# L4PER_PRM register map
Vendor: Texas Instruments
Registers are 32-bit, access per field, reset 0x0 unless marked. A register's access mark holds for its fields unless they carry their own. Offsets are as the file gives them; [hi:lo] are bit positions; {n}, {i} and the like mark numbered series; 'fields as' and 'values as' point back to an identical list.

## L4PER_PRM (part 2 of 2)
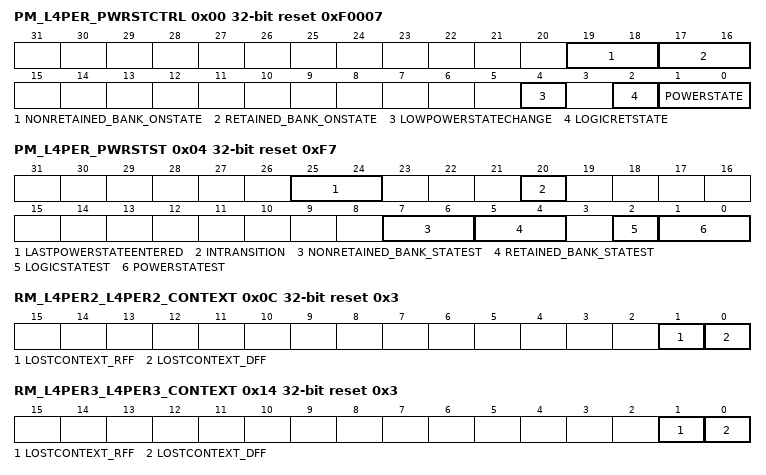
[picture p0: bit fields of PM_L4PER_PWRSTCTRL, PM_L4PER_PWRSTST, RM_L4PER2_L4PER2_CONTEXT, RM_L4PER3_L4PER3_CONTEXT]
0x00 PM_L4PER_PWRSTCTRL reset 0xF0007 — This register controls the L4PER power state to reach upon a domain sleep transition
  [19:18] NONRETAINED_BANK_ONSTATE ro — NONRETAINED_BANK state when domain is ON.
    3=MEM_ON (Memory bank is on when the domain is ON.)
  [17:16] RETAINED_BANK_ONSTATE ro — RETAINED_BANK state when domain is ON.
    3=MEM_ON (Memory bank is on when the domain is ON.)
  [4] LOWPOWERSTATECHANGE rw — Power state change request when domain has already performed a sleep transition. Allows going into deeper low power state without waking up the power domain.
    0=DIS (Do not request a low power state change.); 1=EN (Request a low power state change. This bit is automatically cleared when the power state is effectively changed or when power state is ON.)
  [2] LOGICRETSTATE rw — Logic state when power domain is RETENTION
    0=LOGIC_OFF (Only retention registers are retained and remaing logic is off when the domain is in RETENTION state.); 1=LOGIC_RET (Whole logic is retained when domain is in RETENTION state.)
  [1:0] POWERSTATE rw — Power state control
    1=RET (Reserved); 2=INACT (Reserved); 3=ON (ON State)
0x04 PM_L4PER_PWRSTST reset 0xF7 — This register provides a status on the current L4PER power domain state. [warm reset insensitive]
  [25:24] LASTPOWERSTATEENTERED rw — Last low power state entered. Set to 0x3 upon write of the same only. This register is intended for debug purpose only.
    0=OFF (Power domain was previously OFF); 1=RET (Reserved); 2=INACTIVE (Reserved); 3=ON (Power domain was previously ON-ACTIVE)
  [20] INTRANSITION ro — Domain transition status
    0=NO (No on-going transition on power domain); 1=ONGOING (Power domain transition is in progress.)
  [7:6] NONRETAINED_BANK_STATEST ro — NONRETAINED_BANK state status
    0=MEM_OFF (Memory is OFF); 3=MEM_ON (Memory is ON)
  [5:4] RETAINED_BANK_STATEST ro — RETAINED_BANK state status
    0=MEM_OFF (Memory is OFF); 1=MEM_RET (Reserved); 3=MEM_ON (Memory is ON)
  [2] LOGICSTATEST ro — Logic state status
    0=OFF (Reserved); 1=ON (Logic in domain is ON)
  [1:0] POWERSTATEST ro — Current power state status
    1=RET (Reserved); 2=INACTIVE (Reserved); 3=ON (Power domain is ON-ACTIVE)
0x0C RM_L4PER2_L4PER2_CONTEXT reset 0x3 — This register contains dedicated L4_PER2 context statuses. [warm reset insensitive]
  [1] LOSTCONTEXT_RFF rw — Specify if RFF-based context has been lost due to a previous power transition or other reset source. (set upon assertion of L4PER_PWRON_RET_RST signal)
    0=MAINTAINED (Context has been maintained); 1=LOST (Context has been lost)
  [0] LOSTCONTEXT_DFF rw — Specify if DFF-based context has been lost due to a previous power transition or other reset source. (set upon assertion of L4PER_RST signal)
    values as LOSTCONTEXT_RFF
0x14 RM_L4PER3_L4PER3_CONTEXT reset 0x3 — This register contains dedicated L4_PER3 context statuses. [warm reset insensitive]
  fields as RM_L4PER2_L4PER2_CONTEXT
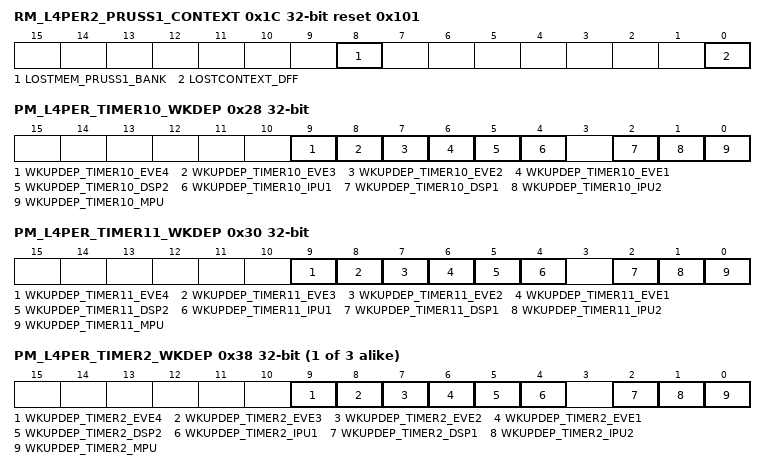
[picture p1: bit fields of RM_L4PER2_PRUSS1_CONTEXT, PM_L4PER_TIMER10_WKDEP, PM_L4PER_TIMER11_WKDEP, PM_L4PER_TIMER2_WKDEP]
0x1C RM_L4PER2_PRUSS1_CONTEXT reset 0x101 — This register contains dedicated PRU-ICSS1 context statuses. [warm reset insensitive]Programmable Real-Time Unit and Industrial Communication Subsystems (PRU-ICSS) is not supported in this family of devices.
  [8] LOSTMEM_PRUSS1_BANK rw — Specify if memory-based context in PRU-ICSS memory bank has been lost due to a previous power transition or other reset source.
    values as RM_L4PER2_L4PER2_CONTEXT.LOSTCONTEXT_RFF
  [0] LOSTCONTEXT_DFF rw — Specify if DFF-based context has been lost due to a previous power transition or other reset source. (set upon assertion of L3INIT_RST signal)
    values as RM_L4PER2_L4PER2_CONTEXT.LOSTCONTEXT_RFF
0x28 PM_L4PER_TIMER10_WKDEP — This register controls wakeup dependency based on TIMER10 service requests.
  [9] WKUPDEP_TIMER10_EVE4 rw — Wakeup dependency from TIMER10 module (SWakeup IRQ signal) towards EVE4 + L3_MAIN1 + L4PER1 + L4PER2 + L4PER3 domainsEVE4 is not supported in this family of devices.
    0=DISABLED (Dependency is disabled); 1=ENABLED (Dependency is enabled)
  [8] WKUPDEP_TIMER10_EVE3 rw — Wakeup dependency from TIMER10 module (SWakeup IRQ signal) towards EVE3 + L3_MAIN1 + L4PER1 + L4PER2 + L4PER3 domainsEVE3 is not supported in this family of devices.
    values as WKUPDEP_TIMER10_EVE4
  [7] WKUPDEP_TIMER10_EVE2 rw — Wakeup dependency from TIMER10 module (SWakeup IRQ signal) towards EVE2 + L3_MAIN1 + L4PER1 + L4PER2 + L4PER3 domains
    values as WKUPDEP_TIMER10_EVE4
  [6] WKUPDEP_TIMER10_EVE1 rw — Wakeup dependency from TIMER10 module (SWakeup IRQ signal) towards EVE1 + L3_MAIN1 + L4PER1 + L4PER2 + L4PER3 domains
    values as WKUPDEP_TIMER10_EVE4
  [5] WKUPDEP_TIMER10_DSP2 rw — Wakeup dependency from TIMER10 module (SWakeup IRQ signal) towards DSP2 + L3_MAIN1 + L4PER1 + L4PER2 + L4PER3 domains
    values as WKUPDEP_TIMER10_EVE4
  [4] WKUPDEP_TIMER10_IPU1 rw — Wakeup dependency from TIMER10 module (SWakeup IRQ signal) towards IPU1 + L3_MAIN1 + L4PER1 + L4PER2 + L4PER3 domains
    values as WKUPDEP_TIMER10_EVE4
  [2] WKUPDEP_TIMER10_DSP1 rw — Wakeup dependency from TIMER10 module (SWakeup IRQ signal) towards DSP1 + L3_MAIN1 + L4PER1 + L4PER2 + L4PER3 domains
    values as WKUPDEP_TIMER10_EVE4
  [1] WKUPDEP_TIMER10_IPU2 rw — Wakeup dependency from TIMER10 module (SWakeup IRQ signal) towards IPU2 + L3_MAIN1 + L4PER1 + L4PER2 + L4PER3 domains
    0=Dependency_is_disabled; 1=Dependency_is_enabled
  [0] WKUPDEP_TIMER10_MPU rw — Wakeup dependency from TIMER10 module (SWakeup IRQ signal) towards MPU + L3_MAIN1 + L4PER1 + L4PER2 + L4PER3 domains
    values as WKUPDEP_TIMER10_EVE4
0x2C RM_L4PER_TIMER10_CONTEXT reset 0x1 — This register contains dedicated TIMER10 context statuses. [warm reset insensitive]
  [0] LOSTCONTEXT_DFF rw — Specify if DFF-based context has been lost due to a previous power transition or other reset source. (set upon assertion of L4PER_RST signal)
    values as RM_L4PER2_L4PER2_CONTEXT.LOSTCONTEXT_RFF
0x30 PM_L4PER_TIMER11_WKDEP — This register controls wakeup dependency based on TIMER11 service requests.
  [9] WKUPDEP_TIMER11_EVE4 rw — Wakeup dependency from TIMER11 module (SWakeup IRQ signal) towards EVE4 + L3_MAIN1 + L4PER1 + L4PER2 + L4PER3 domainsEVE4 is not supported in this family of devices.
    values as PM_L4PER_TIMER10_WKDEP.WKUPDEP_TIMER10_EVE4
  [8] WKUPDEP_TIMER11_EVE3 rw — Wakeup dependency from TIMER11 module (SWakeup IRQ signal) towards EVE3 + L3_MAIN1 + L4PER1 + L4PER2 + L4PER3 domainsEVE3 is not supported in this family of devices.
    values as PM_L4PER_TIMER10_WKDEP.WKUPDEP_TIMER10_EVE4
  [7] WKUPDEP_TIMER11_EVE2 rw — Wakeup dependency from TIMER11 module (SWakeup IRQ signal) towards EVE2 + L3_MAIN1 + L4PER1 + L4PER2 + L4PER3 domains
    values as PM_L4PER_TIMER10_WKDEP.WKUPDEP_TIMER10_EVE4
  [6] WKUPDEP_TIMER11_EVE1 rw — Wakeup dependency from TIMER11 module (SWakeup IRQ signal) towards EVE1 + L3_MAIN1 + L4PER1 + L4PER2 + L4PER3 domains
    values as PM_L4PER_TIMER10_WKDEP.WKUPDEP_TIMER10_EVE4
  [5] WKUPDEP_TIMER11_DSP2 rw — Wakeup dependency from TIMER11 module (SWakeup IRQ signal) towards DSP2 + L3_MAIN1 + L4PER1 + L4PER2 + L4PER3 domains
    values as PM_L4PER_TIMER10_WKDEP.WKUPDEP_TIMER10_EVE4
  [4] WKUPDEP_TIMER11_IPU1 rw — Wakeup dependency from TIMER11 module (SWakeup IRQ signal) towards IPU1 + L3_MAIN1 + L4PER1 + L4PER2 + L4PER3 domains
    values as PM_L4PER_TIMER10_WKDEP.WKUPDEP_TIMER10_EVE4
  [2] WKUPDEP_TIMER11_DSP1 rw — Wakeup dependency from TIMER11 module (SWakeup IRQ signal) towards DSP1 + L3_MAIN1 + L4PER1 + L4PER2 + L4PER3 domains
    values as PM_L4PER_TIMER10_WKDEP.WKUPDEP_TIMER10_EVE4
  [1] WKUPDEP_TIMER11_IPU2 rw — Wakeup dependency from TIMER11 module (SWakeup IRQ signal) towards IPU2 + L3_MAIN1 + L4PER1 + L4PER2 + L4PER3 domains
    0=Dependency_is_disabled; 1=Dependency_is_enabled
  [0] WKUPDEP_TIMER11_MPU rw — Wakeup dependency from TIMER11 module (SWakeup IRQ signal) towards MPU + L3_MAIN1 + L4PER1 + L4PER2 + L4PER3 domains
    values as PM_L4PER_TIMER10_WKDEP.WKUPDEP_TIMER10_EVE4
0x34 RM_L4PER_TIMER11_CONTEXT reset 0x1 — This register contains dedicated TIMER11 context statuses. [warm reset insensitive]
  fields as RM_L4PER_TIMER10_CONTEXT
{0x28+8i} PM_L4PER_TIMER{i}_WKDEP (i=2..4) — This register controls wakeup dependency based on TIMER{i} service requests.
  [9] WKUPDEP_TIMER{i}_EVE4 rw — Wakeup dependency from TIMER{i} module (SWakeup IRQ signal) towards EVE4 + L3_MAIN1 + L4PER1 + L4PER2 + L4PER3 domainsEVE4 is not supported in this family of devices.
    values as PM_L4PER_TIMER10_WKDEP.WKUPDEP_TIMER10_EVE4
  [8] WKUPDEP_TIMER{i}_EVE3 rw — Wakeup dependency from TIMER{i} module (SWakeup IRQ signal) towards EVE3 + L3_MAIN1 + L4PER1 + L4PER2 + L4PER3 domainsEVE3 is not supported in this family of devices.
    values as PM_L4PER_TIMER10_WKDEP.WKUPDEP_TIMER10_EVE4
  [7] WKUPDEP_TIMER{i}_EVE2 rw — Wakeup dependency from TIMER{i} module (SWakeup IRQ signal) towards EVE2 + L3_MAIN1 + L4PER1 + L4PER2 + L4PER3 domains
    values as PM_L4PER_TIMER10_WKDEP.WKUPDEP_TIMER10_EVE4
  [6] WKUPDEP_TIMER{i}_EVE1 rw — Wakeup dependency from TIMER{i} module (SWakeup IRQ signal) towards EVE1 + L3_MAIN1 + L4PER1 + L4PER2 + L4PER3 domains
    values as PM_L4PER_TIMER10_WKDEP.WKUPDEP_TIMER10_EVE4
  [5] WKUPDEP_TIMER{i}_DSP2 rw — Wakeup dependency from TIMER{i} module (SWakeup IRQ signal) towards DSP2 + L3_MAIN1 + L4PER1 + L4PER2 + L4PER3 domains
    values as PM_L4PER_TIMER10_WKDEP.WKUPDEP_TIMER10_EVE4
  [4] WKUPDEP_TIMER{i}_IPU1 rw — Wakeup dependency from TIMER{i} module (SWakeup IRQ signal) towards IPU1 + L3_MAIN1 + L4PER1 + L4PER2 + L4PER3 domains
    values as PM_L4PER_TIMER10_WKDEP.WKUPDEP_TIMER10_EVE4
  [2] WKUPDEP_TIMER{i}_DSP1 rw — Wakeup dependency from TIMER{i} module (SWakeup IRQ signal) towards DSP1 + L3_MAIN1 + L4PER1 + L4PER2 + L4PER3 domains
    values as PM_L4PER_TIMER10_WKDEP.WKUPDEP_TIMER10_EVE4
  [1] WKUPDEP_TIMER{i}_IPU2 rw — Wakeup dependency from TIMER{i} module (SWakeup IRQ signal) towards IPU2 + L3_MAIN1 + L4PER1 + L4PER2 + L4PER3 domains
    0=Dependency_is_disabled; 1=Dependency_is_enabled
  [0] WKUPDEP_TIMER{i}_MPU rw — Wakeup dependency from TIMER{i} module (SWakeup IRQ signal) towards MPU + L3_MAIN1 + L4PER1 + L4PER2 + L4PER3 domains
    values as PM_L4PER_TIMER10_WKDEP.WKUPDEP_TIMER10_EVE4
{0x2C+8i} RM_L4PER_TIMER{i}_CONTEXT reset 0x1 (i=2..4) — This register contains dedicated TIMER{i} context statuses. [warm reset insensitive]
  fields as RM_L4PER_TIMER10_CONTEXT
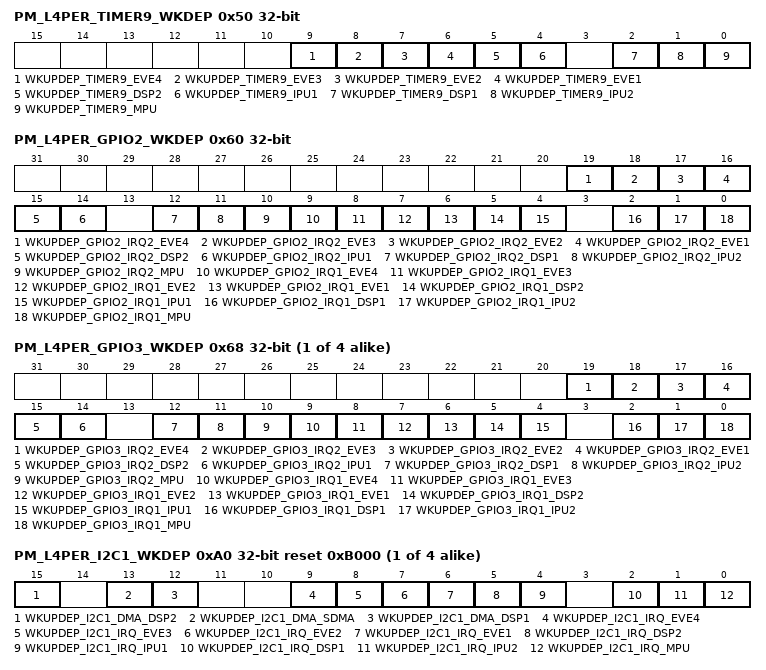
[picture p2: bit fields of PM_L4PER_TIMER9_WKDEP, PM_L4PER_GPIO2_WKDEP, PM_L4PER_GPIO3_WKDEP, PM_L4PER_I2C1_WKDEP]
0x50 PM_L4PER_TIMER9_WKDEP — This register controls wakeup dependency based on TIMER9 service requests.
  [9] WKUPDEP_TIMER9_EVE4 rw — Wakeup dependency from TIMER9 module (SWakeup IRQ signal) towards EVE4 + L3_MAIN1 + L4PER1 + L4PER2 + L4PER3 domainsEVE4 is not supported in this family of devices.
    values as PM_L4PER_TIMER10_WKDEP.WKUPDEP_TIMER10_EVE4
  [8] WKUPDEP_TIMER9_EVE3 rw — Wakeup dependency from TIMER4 module (SWakeup IRQ signal) towards EVE3 + L3_MAIN1 + L4PER1 + L4PER2 + L4PER3 domainsEVE3 is not supported in this family of devices.
    values as PM_L4PER_TIMER10_WKDEP.WKUPDEP_TIMER10_EVE4
  [7] WKUPDEP_TIMER9_EVE2 rw — Wakeup dependency from TIMER9 module (SWakeup IRQ signal) towards EVE2 + L3_MAIN1 + L4PER1 + L4PER2 + L4PER3 domains
    values as PM_L4PER_TIMER10_WKDEP.WKUPDEP_TIMER10_EVE4
  [6] WKUPDEP_TIMER9_EVE1 rw — Wakeup dependency from TIMER9 module (SWakeup IRQ signal) towards EVE1 + L3_MAIN1 + L4PER1 + L4PER2 + L4PER3 domains
    values as PM_L4PER_TIMER10_WKDEP.WKUPDEP_TIMER10_EVE4
  [5] WKUPDEP_TIMER9_DSP2 rw — Wakeup dependency from TIMER4 module (SWakeup IRQ signal) towards DSP2 + L3_MAIN1 + L4PER1 + L4PER2 + L4PER3 domains
    values as PM_L4PER_TIMER10_WKDEP.WKUPDEP_TIMER10_EVE4
  [4] WKUPDEP_TIMER9_IPU1 rw — Wakeup dependency from TIMER9 module (SWakeup IRQ signal) towards IPU1 + L3_MAIN1 + L4PER1 + L4PER2 + L4PER3 domains
    values as PM_L4PER_TIMER10_WKDEP.WKUPDEP_TIMER10_EVE4
  [2] WKUPDEP_TIMER9_DSP1 rw — Wakeup dependency from TIMER4 module (SWakeup IRQ signal) towards DSP1 + L3_MAIN1 + L4PER1 + L4PER2 + L4PER3 domains
    values as PM_L4PER_TIMER10_WKDEP.WKUPDEP_TIMER10_EVE4
  [1] WKUPDEP_TIMER9_IPU2 rw — Wakeup dependency from TIMER9 module (SWakeup IRQ signal) towards IPU2 + L3_MAIN1 + L4PER1 + L4PER2 + L4PER3 domains
    0=Dependency_is_disabled; 1=Dependency_is_enabled
  [0] WKUPDEP_TIMER9_MPU rw — Wakeup dependency from TIMER4 module (SWakeup IRQ signal) towards MPU + L3_MAIN1 + L4PER1 + L4PER2 + L4PER3 domains
    values as PM_L4PER_TIMER10_WKDEP.WKUPDEP_TIMER10_EVE4
0x54 RM_L4PER_TIMER9_CONTEXT reset 0x1 — This register contains dedicated TIMER9 context statuses. [warm reset insensitive]
  fields as RM_L4PER_TIMER10_CONTEXT
0x5C RM_L4PER_ELM_CONTEXT reset 0x1 — This register contains dedicated ELM context statuses. [warm reset insensitive]
  fields as RM_L4PER_TIMER10_CONTEXT
0x60 PM_L4PER_GPIO2_WKDEP — This register controls wakeup dependency based on GPIO2 service requests.
  [19] WKUPDEP_GPIO2_IRQ2_EVE4 rw — Wakeup dependency from GPIO2 module (SWakeup signal) towards EVE4 + L3_MAIN1 + L4PER1 + L4PER2 + L4PER3 domainsEVE4 is not supported in this family of devices.
    values as PM_L4PER_TIMER10_WKDEP.WKUPDEP_TIMER10_EVE4
  [18] WKUPDEP_GPIO2_IRQ2_EVE3 rw — Wakeup dependency from GPIO2 module (SWakeup signal) towards EVE3 + L3_MAIN1 + L4PER1 + L4PER2 + L4PER3 domainsEVE3 is not supported in this family of devices.
    values as PM_L4PER_TIMER10_WKDEP.WKUPDEP_TIMER10_EVE4
  [17] WKUPDEP_GPIO2_IRQ2_EVE2 rw — Wakeup dependency from GPIO2 module (SWakeup signal) towards EVE2 + L3_MAIN1 + L4PER1 + L4PER2 + L4PER3 domains
    values as PM_L4PER_TIMER10_WKDEP.WKUPDEP_TIMER10_EVE4
  [16] WKUPDEP_GPIO2_IRQ2_EVE1 rw — Wakeup dependency from GPIO2 module (SWakeup signal) towards EVE1 + L3_MAIN1 + L4PER1 + L4PER2 + L4PER3 domains
    values as PM_L4PER_TIMER10_WKDEP.WKUPDEP_TIMER10_EVE4
  [15] WKUPDEP_GPIO2_IRQ2_DSP2 rw — Wakeup dependency from GPIO2 module (SWakeup signal) towards DSP2 + L3_MAIN1 + L4PER1 + L4PER2 + L4PER3 domains
    values as PM_L4PER_TIMER10_WKDEP.WKUPDEP_TIMER10_EVE4
  [14] WKUPDEP_GPIO2_IRQ2_IPU1 rw — Wakeup dependency from GPIO2 module (SWakeup signal) towards IPU1 + L3_MAIN1 + L4PER1 + L4PER2 + L4PER3 domains
    values as PM_L4PER_TIMER10_WKDEP.WKUPDEP_TIMER10_EVE4
  [12] WKUPDEP_GPIO2_IRQ2_DSP1 rw — Wakeup dependency from GPIO2 module (SWakeup signal) towards DSP1 + L3MAIN1 + L4PER1 + L4PER2 + L4PER3 domains
    values as PM_L4PER_TIMER10_WKDEP.WKUPDEP_TIMER10_EVE4
  [11] WKUPDEP_GPIO2_IRQ2_IPU2 rw — Wakeup dependency from GPIO2 module (SWakeup signal) towards IPU2 + L3_MAIN1 + L4PER1 + L4PER2 + L4PER3 domains
    0=Dependency_is_disabled; 1=Dependency_is_enabled
  [10] WKUPDEP_GPIO2_IRQ2_MPU rw — Wakeup dependency from GPIO2 module (SWakeup signal) towards MPU + L3_MAIN1 + L4PER1 + L4PER2 + L4PER3 domains
    values as PM_L4PER_TIMER10_WKDEP.WKUPDEP_TIMER10_EVE4
  [9] WKUPDEP_GPIO2_IRQ1_EVE4 rw — Wakeup dependency from GPIO2 module (SWakeup signal) towards EVE4 + L3_MAIN1 + L4PER1 + L4PER2 + L4PER3 domainsEVE4 is not supported in this family of devices.
    values as PM_L4PER_TIMER10_WKDEP.WKUPDEP_TIMER10_EVE4
  [8] WKUPDEP_GPIO2_IRQ1_EVE3 rw — Wakeup dependency from GPIO2 module (SWakeup signal) towards EVE3 + L3_MAIN1 + L4PER1 + L4PER2 + L4PER3 domainsEVE3 is not supported in this family of devices.
    values as PM_L4PER_TIMER10_WKDEP.WKUPDEP_TIMER10_EVE4
  [7] WKUPDEP_GPIO2_IRQ1_EVE2 rw — Wakeup dependency from GPIO2 module (SWakeup signal) towards EVE2 + L3_MAIN1 + L4PER1 + L4PER2 + L4PER3 domains
    values as PM_L4PER_TIMER10_WKDEP.WKUPDEP_TIMER10_EVE4
  [6] WKUPDEP_GPIO2_IRQ1_EVE1 rw — Wakeup dependency from GPIO2 module (SWakeup signal) towards EVE1 + L3_MAIN1 + L4PER1 + L4PER2 + L4PER3 domains
    values as PM_L4PER_TIMER10_WKDEP.WKUPDEP_TIMER10_EVE4
  [5] WKUPDEP_GPIO2_IRQ1_DSP2 rw — Wakeup dependency from GPIO2 module (SWakeup signal) towards DSP2 + L3_MAIN1 + L4PER1 + L4PER2 + L4PER3 domains
    values as PM_L4PER_TIMER10_WKDEP.WKUPDEP_TIMER10_EVE4
  [4] WKUPDEP_GPIO2_IRQ1_IPU1 rw — Wakeup dependency from GPIO2 module (SWakeup signal) towards IPU1 + L3_MAIN1 + L4PER1 + L4PER2 + L4PER3 domains
    values as PM_L4PER_TIMER10_WKDEP.WKUPDEP_TIMER10_EVE4
  [2] WKUPDEP_GPIO2_IRQ1_DSP1 rw — Wakeup dependency from GPIO2 module (SWakeup signal) towards DSP1 + L3_MAIN1 + L4PER1 + L4PER2 + L4PER3 domains
    values as PM_L4PER_TIMER10_WKDEP.WKUPDEP_TIMER10_EVE4
  [1] WKUPDEP_GPIO2_IRQ1_IPU2 rw — Wakeup dependency from GPIO2 module (SWakeup signal) towards IPU2 + L3_MAIN1 + L4PER1 + L4PER2 + L4PER3 domains
    0=Dependency_is_disabled; 1=Dependency_is_enabled
  [0] WKUPDEP_GPIO2_IRQ1_MPU rw — Wakeup dependency from GPIO2 module (SWakeup signal for POROCPSINTERRUPT1) towards MPU + L3_MAIN1 + L4PER1 + L4PER2 + L4PER3 domains
    values as PM_L4PER_TIMER10_WKDEP.WKUPDEP_TIMER10_EVE4
{0x54+8i} RM_L4PER_GPIO{i}_CONTEXT reset 0x2 (i=2..6) — This register contains dedicated GPIO{i} context statuses. [warm reset insensitive]
  [1] LOSTCONTEXT_RFF rw — Specify if RFF-based context has been lost due to a previous power transition or other reset source. (set upon assertion of L4PER_RET_RST signal)
    values as RM_L4PER2_L4PER2_CONTEXT.LOSTCONTEXT_RFF
{0x50+8i} PM_L4PER_GPIO{i}_WKDEP (i=3..6) — This register controls wakeup dependency based on GPIO{i} service requests.
  [19] WKUPDEP_GPIO{i}_IRQ2_EVE4 rw — Wakeup dependency from GPIO{i} module (SWakeup signal) towards EVE4 + L3_MAIN1 + L4PER1 + L4PER2 + L4PER3 domainsEVE4 is not supported in this family of devices.
    values as PM_L4PER_TIMER10_WKDEP.WKUPDEP_TIMER10_EVE4
  [18] WKUPDEP_GPIO{i}_IRQ2_EVE3 rw — Wakeup dependency from GPIO{i} module (SWakeup signal) towards EVE3 + L3_MAIN1 + L4PER1 + L4PER2 + L4PER3 domainsEVE3 is not supported in this family of devices.
    values as PM_L4PER_TIMER10_WKDEP.WKUPDEP_TIMER10_EVE4
  [17] WKUPDEP_GPIO{i}_IRQ2_EVE2 rw — Wakeup dependency from GPIO{i} module (SWakeup signal) towards EVE2 + L3_MAIN1 + L4PER1 + L4PER2 + L4PER3 domains
    values as PM_L4PER_TIMER10_WKDEP.WKUPDEP_TIMER10_EVE4
  [16] WKUPDEP_GPIO{i}_IRQ2_EVE1 rw — Wakeup dependency from GPIO{i} module (SWakeup signal) towards EVE1 + L3_MAIN1 + L4PER1 + L4PER2 + L4PER3 domains
    values as PM_L4PER_TIMER10_WKDEP.WKUPDEP_TIMER10_EVE4
  [15] WKUPDEP_GPIO{i}_IRQ2_DSP2 rw — Wakeup dependency from GPIO{i} module (SWakeup signal) towards DSP2 + L3_MAIN1 + L4PER1 + L4PER2 + L4PER3 domains
    values as PM_L4PER_TIMER10_WKDEP.WKUPDEP_TIMER10_EVE4
  [14] WKUPDEP_GPIO{i}_IRQ2_IPU1 rw — Wakeup dependency from GPIO{i} module (SWakeup signal) towards IPU1 + L3_MAIN1 + L4PER1 + L4PER2 + L4PER3 domains
    values as PM_L4PER_TIMER10_WKDEP.WKUPDEP_TIMER10_EVE4
  [12] WKUPDEP_GPIO{i}_IRQ2_DSP1 rw — Wakeup dependency from GPIO{i} module (SWakeup signal) towards DSP1 + L3_MAIN1 + L4PER1 + L4PER2 + L4PER3 domains
    values as PM_L4PER_TIMER10_WKDEP.WKUPDEP_TIMER10_EVE4
  [11] WKUPDEP_GPIO{i}_IRQ2_IPU2 rw — Wakeup dependency from GPIO{i} module (SWakeup signal) towards IPU2 + L3_MAIN1 + L4PER1 + L4PER2 + L4PER3 domains
    0=Dependency_is_disabled; 1=Dependency_is_enabled
  [10] WKUPDEP_GPIO{i}_IRQ2_MPU rw — Wakeup dependency from GPIO{i} module (SWakeup signal) towards MPU + L3_MAIN1 + L4PER1 + L4PER2 + L4PER3 domains
    values as PM_L4PER_TIMER10_WKDEP.WKUPDEP_TIMER10_EVE4
  [9] WKUPDEP_GPIO{i}_IRQ1_EVE4 rw — Wakeup dependency from GPIO{i} module (SWakeup signal) towards EVE4 + L3_MAIN1 + L4PER1 + L4PER2 + L4PER3 domainsEVE4 is not supported in this family of devices.
    values as PM_L4PER_TIMER10_WKDEP.WKUPDEP_TIMER10_EVE4
  [8] WKUPDEP_GPIO{i}_IRQ1_EVE3 rw — Wakeup dependency from GPIO{i} module (SWakeup signal) towards EVE3 + L3_MAIN1 + L4PER1 + L4PER2 + L4PER3 domainsEVE3 is not supported in this family of devices.
    values as PM_L4PER_TIMER10_WKDEP.WKUPDEP_TIMER10_EVE4
  [7] WKUPDEP_GPIO{i}_IRQ1_EVE2 rw — Wakeup dependency from GPIO{i} module (SWakeup signal) towards EVE2 + L3_MAIN1 + L4PER1 + L4PER2 + L4PER3 domains
    values as PM_L4PER_TIMER10_WKDEP.WKUPDEP_TIMER10_EVE4
  [6] WKUPDEP_GPIO{i}_IRQ1_EVE1 rw — Wakeup dependency from GPIO{i} module (SWakeup signal) towards EVE1 + L3_MAIN1 + L4PER1 + L4PER2 + L4PER3 domains
    values as PM_L4PER_TIMER10_WKDEP.WKUPDEP_TIMER10_EVE4
  [5] WKUPDEP_GPIO{i}_IRQ1_DSP2 rw — Wakeup dependency from GPIO{i} module (SWakeup signal) towards DSP2 + L3_MAIN1 + L4PER1 + L4PER2 + L4PER3 domains
    values as PM_L4PER_TIMER10_WKDEP.WKUPDEP_TIMER10_EVE4
  [4] WKUPDEP_GPIO{i}_IRQ1_IPU1 rw — Wakeup dependency from GPIO{i} module (SWakeup signal) towards IPU1 + L3_MAIN1 + L4PER1 + L4PER2 + L4PER3 domains
    values as PM_L4PER_TIMER10_WKDEP.WKUPDEP_TIMER10_EVE4
  [2] WKUPDEP_GPIO{i}_IRQ1_DSP1 rw — Wakeup dependency from GPIO{i} module (SWakeup signal) towards DSP1 + L3_MAIN1 + L4PER1 + L4PER2 + L4PER3 domains
    values as PM_L4PER_TIMER10_WKDEP.WKUPDEP_TIMER10_EVE4
  [1] WKUPDEP_GPIO{i}_IRQ1_IPU2 rw — Wakeup dependency from GPIO{i} module (SWakeup signal) towards IPU2 + L3_MAIN1 + L4PER1 + L4PER2 + L4PER3 domains
    0=Dependency_is_disabled; 1=Dependency_is_enabled
  [0] WKUPDEP_GPIO{i}_IRQ1_MPU rw — Wakeup dependency from GPIO{i} module (SWakeup signal) towards MPU + L3_MAIN1 + L4PER1 + L4PER2 + L4PER3 domains
    values as PM_L4PER_TIMER10_WKDEP.WKUPDEP_TIMER10_EVE4
0x94 RM_L4PER2_PWMSS2_CONTEXT reset 0x1 — This register contains dedicated PWMSS2 context statuses. [warm reset insensitive]
  [0] LOSTCONTEXT_DFF rw — Specify if DFF-based context has been lost due to a previous power transition or other reset source. (set upon assertion of CORE_RET_RST signal)
    values as RM_L4PER2_L4PER2_CONTEXT.LOSTCONTEXT_RFF
0x9C RM_L4PER2_PWMSS3_CONTEXT reset 0x1 — This register contains dedicated PWMSS3 context statuses. [warm reset insensitive]
  fields as RM_L4PER2_PWMSS2_CONTEXT
{0x98+8i} PM_L4PER_I2C{i}_WKDEP reset 0xB000 (i=1..4) — This register controls wakeup dependency based on I2C{i} service requests.
  [15] WKUPDEP_I2C{i}_DMA_DSP2 rw — Wakeup dependency from I2C{i} module (SWakeup_dma signal) towards DSP2 + L3_MAIN1 + L4PER1 + L4PER2 + L4PER3 domains
    values as PM_L4PER_TIMER10_WKDEP.WKUPDEP_TIMER10_EVE4
  [13] WKUPDEP_I2C{i}_DMA_SDMA rw — Wakeup dependency from I2C{i} module (SWakeup_dma signal) towards SDMA + L3MAIN1 + L4PER1 + L4PER2 + L4PER3 domains
    0=Dependency_is_disabled; 1=Dependency_is_enabled
  [12] WKUPDEP_I2C{i}_DMA_DSP1 rw — Wakeup dependency from I2C{i} module (SWakeup_dma signal) towards DSP1 + L3_MAIN1 + L4PER1 + L4PER2 + L4PER3 domains
    values as PM_L4PER_TIMER10_WKDEP.WKUPDEP_TIMER10_EVE4
  [9] WKUPDEP_I2C{i}_IRQ_EVE4 rw — Wakeup dependency from I2C{i} module (SWakeup IRQ signal) towards EVE4 + L3_MAIN1 + L4PER1 + L4PER2 + L4PER3 domainsEVE4 is not supported in this family of devices.
    values as PM_L4PER_TIMER10_WKDEP.WKUPDEP_TIMER10_EVE4
  [8] WKUPDEP_I2C{i}_IRQ_EVE3 rw — Wakeup dependency from I2C{i} module (SWakeup IRQ signal) towards EVE3 + L3_MAIN1 + L4PER1 + L4PER2 + L4PER3 domainsEVE3 is not supported in this family of devices.
    values as PM_L4PER_TIMER10_WKDEP.WKUPDEP_TIMER10_EVE4
  [7] WKUPDEP_I2C{i}_IRQ_EVE2 rw — Wakeup dependency from I2C{i} module (SWakeup IRQ signal) towards EVE2 + L3_MAIN1 + L4PER1 + L4PER2 + L4PER3 domains
    values as PM_L4PER_TIMER10_WKDEP.WKUPDEP_TIMER10_EVE4
  [6] WKUPDEP_I2C{i}_IRQ_EVE1 rw — Wakeup dependency from I2C{i} module (SWakeup IRQ signal) towards EVE1 + L3_MAIN1 + L4PER1 + L4PER2 + L4PER3 domains
    values as PM_L4PER_TIMER10_WKDEP.WKUPDEP_TIMER10_EVE4
  [5] WKUPDEP_I2C{i}_IRQ_DSP2 rw — Wakeup dependency from I2C{i} module (SWakeup IRQ signal) towards DSP2 + L3_MAIN1 + L4PER1 + L4PER2 + L4PER3 domains
    values as PM_L4PER_TIMER10_WKDEP.WKUPDEP_TIMER10_EVE4
  [4] WKUPDEP_I2C{i}_IRQ_IPU1 rw — Wakeup dependency from I2C{i} module (SWakeup IRQ signal) towards IPU1 + L3_MAIN1 + L4PER1 + L4PER2 + L4PER3 domains
    values as PM_L4PER_TIMER10_WKDEP.WKUPDEP_TIMER10_EVE4
  [2] WKUPDEP_I2C{i}_IRQ_DSP1 rw — Wakeup dependency from I2C{i} module (SWakeup IRQ signal) towards DSP1 + L3_MAIN1 + L4PER1 + L4PER2 + L4PER3 domains
    values as PM_L4PER_TIMER10_WKDEP.WKUPDEP_TIMER10_EVE4
  [1] WKUPDEP_I2C{i}_IRQ_IPU2 rw — Wakeup dependency from I2C{i} module (SWakeup IRQ signal) towards IPU2 + L3_MAIN1 + L4PER1 + L4PER2 + L4PER3 domains
    0=Dependency_is_disabled; 1=Dependency_is_enabled
  [0] WKUPDEP_I2C{i}_IRQ_MPU rw — Wakeup dependency from I2C{i} module (SWakeup IRQ signal) towards MPU + L3_MAIN1 + L4PER1 + L4PER2 + L4PER3 domains
    values as PM_L4PER_TIMER10_WKDEP.WKUPDEP_TIMER10_EVE4
0xA4 RM_L4PER_I2C1_CONTEXT reset 0x2 — This register contains dedicated I2C1 context statuses. [warm reset insensitive]
  fields as RM_L4PER_GPIO2_CONTEXT
{0x9C+8i} RM_L4PER_I2C{i}_CONTEXT reset 0x1 (i=2..4) — This register contains dedicated I2C{i} context statuses. [warm reset insensitive]
  fields as RM_L4PER_TIMER10_CONTEXT
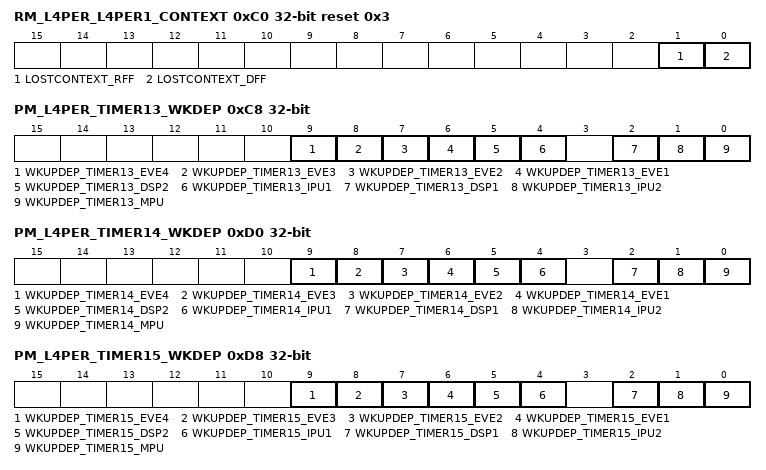
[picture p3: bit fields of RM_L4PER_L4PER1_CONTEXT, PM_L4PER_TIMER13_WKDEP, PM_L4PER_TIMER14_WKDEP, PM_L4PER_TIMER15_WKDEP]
0xC0 RM_L4PER_L4PER1_CONTEXT reset 0x3 — This register contains dedicated L4_PER1 context statuses. [warm reset insensitive]
  fields as RM_L4PER2_L4PER2_CONTEXT
0xC4 RM_L4PER2_PWMSS1_CONTEXT reset 0x1 — This register contains dedicated PWMSS1 context statuses. [warm reset insensitive]
  fields as RM_L4PER2_PWMSS2_CONTEXT
0xC8 PM_L4PER_TIMER13_WKDEP — This register controls wakeup dependency based on TIMER13 service requests.
  [9] WKUPDEP_TIMER13_EVE4 rw — Wakeup dependency from TIMER13 module (SWakeup IRQ signal) towards EVE4 + L3_MAIN1 + L4PER1 + L4PER2 + L4PER3 domainsEVE4 is not supported in this family of devices.
    values as PM_L4PER_TIMER10_WKDEP.WKUPDEP_TIMER10_EVE4
  [8] WKUPDEP_TIMER13_EVE3 rw — Wakeup dependency from TIMER13 module (SWakeup IRQ signal) towards EVE3 + L3_MAIN1 + L4PER1 + L4PER2 + L4PER3 domainsEVE3 is not supported in this family of devices.
    values as PM_L4PER_TIMER10_WKDEP.WKUPDEP_TIMER10_EVE4
  [7] WKUPDEP_TIMER13_EVE2 rw — Wakeup dependency from TIMER13 module (SWakeup IRQ signal) towards EVE2 + L3_MAIN1 + L4PER1 + L4PER2 + L4PER3 domains
    values as PM_L4PER_TIMER10_WKDEP.WKUPDEP_TIMER10_EVE4
  [6] WKUPDEP_TIMER13_EVE1 rw — Wakeup dependency from TIMER13 module (SWakeup IRQ signal) towards EVE1 + L3_MAIN1 + L4PER1 + L4PER2 + L4PER3 domains
    values as PM_L4PER_TIMER10_WKDEP.WKUPDEP_TIMER10_EVE4
  [5] WKUPDEP_TIMER13_DSP2 rw — Wakeup dependency from TIMER13 module (SWakeup IRQ signal) towards DSP2 + L3_MAIN1 + L4PER1 + L4PER2 + L4PER3 domains
    values as PM_L4PER_TIMER10_WKDEP.WKUPDEP_TIMER10_EVE4
  [4] WKUPDEP_TIMER13_IPU1 rw — Wakeup dependency from TIMER13 module (SWakeup IRQ signal) towards IPU1 + L3_MAIN1 + L4PER1 + L4PER2 + L4PER3 domains
    values as PM_L4PER_TIMER10_WKDEP.WKUPDEP_TIMER10_EVE4
  [2] WKUPDEP_TIMER13_DSP1 rw — Wakeup dependency from TIMER13 module (SWakeup IRQ signal) towards DSP1 + L3_MAIN1 + L4PER1 + L4PER2 + L4PER3 domains
    values as PM_L4PER_TIMER10_WKDEP.WKUPDEP_TIMER10_EVE4
  [1] WKUPDEP_TIMER13_IPU2 rw — Wakeup dependency from TIMER13 module (SWakeup IRQ signal) towards IPU2 + L3_MAIN1 + L4PER1 + L4PER2 + L4PER3 domains
    0=Dependency_is_disabled; 1=Dependency_is_enabled
  [0] WKUPDEP_TIMER13_MPU rw — Wakeup dependency from TIMER13 module (SWakeup IRQ signal) towards MPU + L3_MAIN1 + L4PER1 + L4PER2 + L4PER3 domains
    values as PM_L4PER_TIMER10_WKDEP.WKUPDEP_TIMER10_EVE4
{0x64+8i} RM_L4PER3_TIMER{i}_CONTEXT reset 0x1 (i=13..15) — This register contains dedicated TIMER{i} context statuses. [warm reset insensitive]
  fields as RM_L4PER_TIMER10_CONTEXT
0xD0 PM_L4PER_TIMER14_WKDEP — This register controls wakeup dependency based on TIMER14 service requests.
  [9] WKUPDEP_TIMER14_EVE4 rw — Wakeup dependency from TIMER14 module (SWakeup IRQ signal) towards EVE4 + L3_MAIN1 + L4PER1 + L4PER2 + L4PER3 domainsEVE4 is not supported in this family of devices.
    values as PM_L4PER_TIMER10_WKDEP.WKUPDEP_TIMER10_EVE4
  [8] WKUPDEP_TIMER14_EVE3 rw — Wakeup dependency from TIMER14 module (SWakeup IRQ signal) towards EVE3 + L3_MAIN1 + L4PER1 + L4PER2 + L4PER3 domainsEVE3 is not supported in this family of devices.
    values as PM_L4PER_TIMER10_WKDEP.WKUPDEP_TIMER10_EVE4
  [7] WKUPDEP_TIMER14_EVE2 rw — Wakeup dependency from TIMER14 module (SWakeup IRQ signal) towards EVE2 + L3_MAIN1 + L4PER1 + L4PER2 + L4PER3 domains
    values as PM_L4PER_TIMER10_WKDEP.WKUPDEP_TIMER10_EVE4
  [6] WKUPDEP_TIMER14_EVE1 rw — Wakeup dependency from TIMER14 module (SWakeup IRQ signal) towards EVE1 + L3_MAIN1 + L4PER1 + L4PER2 + L4PER3 domains
    values as PM_L4PER_TIMER10_WKDEP.WKUPDEP_TIMER10_EVE4
  [5] WKUPDEP_TIMER14_DSP2 rw — Wakeup dependency from TIMER14 module (SWakeup IRQ signal) towards DSP2 + L3_MAIN1 + L4PER1 + L4PER2 + L4PER3 domains
    values as PM_L4PER_TIMER10_WKDEP.WKUPDEP_TIMER10_EVE4
  [4] WKUPDEP_TIMER14_IPU1 rw — Wakeup dependency from TIMER14 module (SWakeup IRQ signal) towards IPU1 + L3_MAIN1 + L4PER1 + L4PER2 + L4PER3 domains
    values as PM_L4PER_TIMER10_WKDEP.WKUPDEP_TIMER10_EVE4
  [2] WKUPDEP_TIMER14_DSP1 rw — Wakeup dependency from TIMER14 module (SWakeup IRQ signal) towards DSP1 + L3_MAIN1 + L4PER1 + L4PER2 + L4PER3 domains
    values as PM_L4PER_TIMER10_WKDEP.WKUPDEP_TIMER10_EVE4
  [1] WKUPDEP_TIMER14_IPU2 rw — Wakeup dependency from TIMER14 module (SWakeup IRQ signal) towards IPU2 + L3_MAIN1 + L4PER1 + L4PER2 + L4PER3 domains
    0=Dependency_is_disabled; 1=Dependency_is_enabled
  [0] WKUPDEP_TIMER14_MPU rw — Wakeup dependency from TIMER14 module (SWakeup IRQ signal) towards MPU + L3_MAIN1 + L4PER1 + L4PER2 + L4PER3 domains
    values as PM_L4PER_TIMER10_WKDEP.WKUPDEP_TIMER10_EVE4
0xD8 PM_L4PER_TIMER15_WKDEP — This register controls wakeup dependency based on TIMER15 service requests.
  [9] WKUPDEP_TIMER15_EVE4 rw — 5Wakeup dependency from TIMER15 module (SWakeup IRQ signal) towards EVE4 + L3_MAIN1 + L4PER1 + L4PER2 + L4PER3 domainsEVE4 is not supported in this family of devices.
    values as PM_L4PER_TIMER10_WKDEP.WKUPDEP_TIMER10_EVE4
  [8] WKUPDEP_TIMER15_EVE3 rw — Wakeup dependency from TIMER15 module (SWakeup IRQ signal) towards EVE3 + L3_MAIN1 + L4PER1 + L4PER2 + L4PER3 domainsEVE3 is not supported in this family of devices.
    values as PM_L4PER_TIMER10_WKDEP.WKUPDEP_TIMER10_EVE4
  [7] WKUPDEP_TIMER15_EVE2 rw — Wakeup dependency from TIMER15 module (SWakeup IRQ signal) towards EVE2 + L3_MAIN1 + L4PER1 + L4PER2 + L4PER3 domains
    values as PM_L4PER_TIMER10_WKDEP.WKUPDEP_TIMER10_EVE4
  [6] WKUPDEP_TIMER15_EVE1 rw — Wakeup dependency from TIMER15 module (SWakeup IRQ signal) towards EVE1 + L3_MAIN1 + L4PER1 + L4PER2 + L4PER3 domains
    values as PM_L4PER_TIMER10_WKDEP.WKUPDEP_TIMER10_EVE4
  [5] WKUPDEP_TIMER15_DSP2 rw — Wakeup dependency from TIMER15 module (SWakeup IRQ signal) towards DSP2 + L3_MAIN1 + L4PER1 + L4PER2 + L4PER3 domains
    values as PM_L4PER_TIMER10_WKDEP.WKUPDEP_TIMER10_EVE4
  [4] WKUPDEP_TIMER15_IPU1 rw — Wakeup dependency from TIMER15 module (SWakeup IRQ signal) towards IPU1 + L3_MAIN1 + L4PER1 + L4PER2 + L4PER3 domains
    values as PM_L4PER_TIMER10_WKDEP.WKUPDEP_TIMER10_EVE4
  [2] WKUPDEP_TIMER15_DSP1 rw — Wakeup dependency from TIMER15 module (SWakeup IRQ signal) towards DSP1 + L3_MAIN1 + L4PER1 + L4PER2 + L4PER3 domains
    values as PM_L4PER_TIMER10_WKDEP.WKUPDEP_TIMER10_EVE4
  [1] WKUPDEP_TIMER15_IPU2 rw — Wakeup dependency from TIMER15 module (SWakeup IRQ signal) towards IPU2 + L3_MAIN1 + L4PER1 + L4PER2 + L4PER3 domains
    0=Dependency_is_disabled; 1=Dependency_is_enabled
  [0] WKUPDEP_TIMER15_MPU rw — Wakeup dependency from TIMER15 module (SWakeup IRQ signal) towards MPU + L3_MAIN1 + L4PER1 + L4PER2 + L4PER3 domains
    values as PM_L4PER_TIMER10_WKDEP.WKUPDEP_TIMER10_EVE4
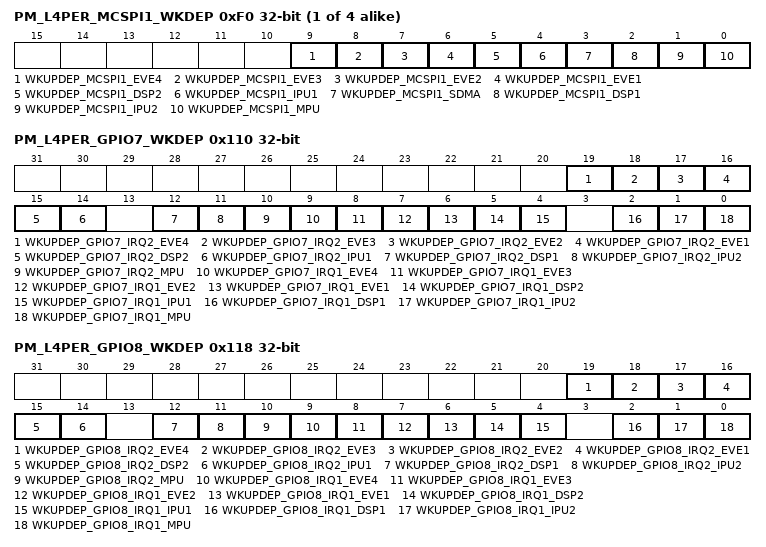
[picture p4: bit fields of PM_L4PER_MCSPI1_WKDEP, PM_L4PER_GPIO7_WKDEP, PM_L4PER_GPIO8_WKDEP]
{0xE8+8i} PM_L4PER_MCSPI{i}_WKDEP (i=1..4) — This register controls wakeup dependency based on MCSPI{i} service requests.
  [9] WKUPDEP_MCSPI{i}_EVE4 rw — Wakeup dependency from MCSPI{i} module (SWakeup signal) towards EVE4 + L3_MAIN1 + L4PER1 + L4PER2 + L4PER3 domainsEVE4 is not supported in this family of devices.
    values as PM_L4PER_TIMER10_WKDEP.WKUPDEP_TIMER10_EVE4
  [8] WKUPDEP_MCSPI{i}_EVE3 rw — Wakeup dependency from MCSPI{i} module (SWakeup signal) towards EVE3 + L3_MAIN1 + L4PER1 + L4PER2 + L4PER3 domainsEVE3 is not supported in this family of devices.
    values as PM_L4PER_TIMER10_WKDEP.WKUPDEP_TIMER10_EVE4
  [7] WKUPDEP_MCSPI{i}_EVE2 rw — Wakeup dependency from MCSPI{i} module (SWakeup signal) towards EVE2 + L3_MAIN1 + L4PER1 + L4PER2 + L4PER3 domains
    values as PM_L4PER_TIMER10_WKDEP.WKUPDEP_TIMER10_EVE4
  [6] WKUPDEP_MCSPI{i}_EVE1 rw — Wakeup dependency from MCSPI{i} module (SWakeup signal) towards EVE1 + L3_MAIN1 + L4PER1 + L4PER2 + L4PER3 domains
    values as PM_L4PER_TIMER10_WKDEP.WKUPDEP_TIMER10_EVE4
  [5] WKUPDEP_MCSPI{i}_DSP2 rw — Wakeup dependency from MCSPI{i} module (SWakeup signal) towards DSP2 + L3_MAIN1 + L4PER1 + L4PER2 + L4PER3 domains
    values as PM_L4PER_TIMER10_WKDEP.WKUPDEP_TIMER10_EVE4
  [4] WKUPDEP_MCSPI{i}_IPU1 rw — Wakeup dependency from MCSPI{i} module (SWakeup signal) towards IPU1 + L3_MAIN1 + L4PER1 + L4PER2 + L4PER3 domains
    values as PM_L4PER_TIMER10_WKDEP.WKUPDEP_TIMER10_EVE4
  [3] WKUPDEP_MCSPI{i}_SDMA rw — Wakeup dependency from MCSPI{i} module (SWakeup signal) towards SDMA + L3MAIN1 + L4PER1 + L4PER2 + L4PER3 domains
    0=Dependency_is_disabled; 1=Dependency_is_enabled
  [2] WKUPDEP_MCSPI{i}_DSP1 rw — Wakeup dependency from MCSPI{i} module (SWakeup signal) towards DSP1 + L3_MAIN1 + L4PER1 + L4PER2 + L4PER3 domains
    values as PM_L4PER_TIMER10_WKDEP.WKUPDEP_TIMER10_EVE4
  [1] WKUPDEP_MCSPI{i}_IPU2 rw — Wakeup dependency from MCSPI{i} module (SWakeup signal) towards IPU2 + L3_MAIN1 + L4PER1 + L4PER2 + L4PER3 domains
    0=Dependency_is_disabled; 1=Dependency_is_enabled
  [0] WKUPDEP_MCSPI{i}_MPU rw — Wakeup dependency from MCSPI{i} module (SWakeup signal) towards MPU + L3_MAIN1 + L4PER1 + L4PER2 + L4PER3 domains
    values as PM_L4PER_TIMER10_WKDEP.WKUPDEP_TIMER10_EVE4
{0xEC+8i} RM_L4PER_MCSPI{i}_CONTEXT reset 0x1 (i=1..4) — This register contains dedicated MCSPI{i} context statuses. [warm reset insensitive]
  fields as RM_L4PER_TIMER10_CONTEXT
0x110 PM_L4PER_GPIO7_WKDEP — This register controls wakeup dependency based on GPIO7 service requests.
  [19] WKUPDEP_GPIO7_IRQ2_EVE4 rw — Wakeup dependency from GPIO7 module (SWakeup signal) towards EVE4 + L3_MAIN1 + L4PER1 + L4PER2 + L4PER3 domainsEVE4 is not supported in this family of devices.
    values as PM_L4PER_TIMER10_WKDEP.WKUPDEP_TIMER10_EVE4
  [18] WKUPDEP_GPIO7_IRQ2_EVE3 rw — Wakeup dependency from GPIO7 module (SWakeup signal) towards EVE3 + L3_MAIN1 + L4PER1 + L4PER2 + L4PER3 domainsEVE3 is not supported in this family of devices.
    values as PM_L4PER_TIMER10_WKDEP.WKUPDEP_TIMER10_EVE4
  [17] WKUPDEP_GPIO7_IRQ2_EVE2 rw — Wakeup dependency from GPIO7 module (SWakeup signal) towards EVE2 + L3_MAIN1 + L4PER1 + L4PER2 + L4PER3 domains
    values as PM_L4PER_TIMER10_WKDEP.WKUPDEP_TIMER10_EVE4
  [16] WKUPDEP_GPIO7_IRQ2_EVE1 rw — Wakeup dependency from GPIO7 module (SWakeup signal) towards EVE1 + L3_MAIN1 + L4PER1 + L4PER2 + L4PER3 domains
    values as PM_L4PER_TIMER10_WKDEP.WKUPDEP_TIMER10_EVE4
  [15] WKUPDEP_GPIO7_IRQ2_DSP2 rw — Wakeup dependency from GPIO7 module (SWakeup signal) towards DSP2 + L3_MAIN1 + L4PER1 + L4PER2 + L4PER3 domains
    values as PM_L4PER_TIMER10_WKDEP.WKUPDEP_TIMER10_EVE4
  [14] WKUPDEP_GPIO7_IRQ2_IPU1 rw — Wakeup dependency from GPIO7 module (SWakeup signal) towards IPU1 + L3_MAIN1 + L4PER1 + L4PER2 + L4PER3 domains
    values as PM_L4PER_TIMER10_WKDEP.WKUPDEP_TIMER10_EVE4
  [12] WKUPDEP_GPIO7_IRQ2_DSP1 rw — Wakeup dependency from GPIO7 module (SWakeup signal) towards DSP1 + L3_MAIN1 + L4PER1 + L4PER2 + L4PER3 domains
    values as PM_L4PER_TIMER10_WKDEP.WKUPDEP_TIMER10_EVE4
  [11] WKUPDEP_GPIO7_IRQ2_IPU2 rw — Wakeup dependency from GPIO7 module (SWakeup signal) towards IPU2 + L3_MAIN1 + L4PER1 + L4PER2 + L4PER3 domains
    0=Dependency_is_disabled; 1=Dependency_is_enabled
  [10] WKUPDEP_GPIO7_IRQ2_MPU rw — Wakeup dependency from GPIO7 module (SWakeup signal) towards MPU + L3_MAIN1 + L4PER1 + L4PER2 + L4PER3 domains
    values as PM_L4PER_TIMER10_WKDEP.WKUPDEP_TIMER10_EVE4
  [9] WKUPDEP_GPIO7_IRQ1_EVE4 rw — Wakeup dependency from GPIO7 module (SWakeup signal) towards EVE4 + L3_MAIN1 + L4PER1 + L4PER2 + L4PER3 domainsEVE4 is not supported in this family of devices.
    values as PM_L4PER_TIMER10_WKDEP.WKUPDEP_TIMER10_EVE4
  [8] WKUPDEP_GPIO7_IRQ1_EVE3 rw — Wakeup dependency from GPIO7 module (SWakeup signal) towards EVE3 + L3_MAIN1 + L4PER1 + L4PER2 + L4PER3 domainsEVE3 is not supported in this family of devices.
    values as PM_L4PER_TIMER10_WKDEP.WKUPDEP_TIMER10_EVE4
  [7] WKUPDEP_GPIO7_IRQ1_EVE2 rw — Wakeup dependency from GPIO7 module (SWakeup signal) towards EVE2 + L3_MAIN1 + L4PER1 + L4PER2 + L4PER3 domains
    values as PM_L4PER_TIMER10_WKDEP.WKUPDEP_TIMER10_EVE4
  [6] WKUPDEP_GPIO7_IRQ1_EVE1 rw — Wakeup dependency from GPIO7 module (SWakeup signal) towards EVE1 + L3_MAIN1 + L4PER1 + L4PER2 + L4PER3 domains
    values as PM_L4PER_TIMER10_WKDEP.WKUPDEP_TIMER10_EVE4
  [5] WKUPDEP_GPIO7_IRQ1_DSP2 rw — Wakeup dependency from GPIO7 module (SWakeup signal) towards DSP2 + L3_MAIN1 + L4PER1 + L4PER2 + L4PER3 domains
    values as PM_L4PER_TIMER10_WKDEP.WKUPDEP_TIMER10_EVE4
  [4] WKUPDEP_GPIO7_IRQ1_IPU1 rw — Wakeup dependency from GPIO7 module (SWakeup signal) towards IPU1 + L3_MAIN1 + L4PER1 + L4PER2 + L4PER3 domains
    values as PM_L4PER_TIMER10_WKDEP.WKUPDEP_TIMER10_EVE4
  [2] WKUPDEP_GPIO7_IRQ1_DSP1 rw — Wakeup dependency from GPIO7 module (SWakeup signal) towards DSP1 + L3_MAIN1 + L4PER1 + L4PER2 + L4PER3 domains
    values as PM_L4PER_TIMER10_WKDEP.WKUPDEP_TIMER10_EVE4
  [1] WKUPDEP_GPIO7_IRQ1_IPU2 rw — Wakeup dependency from GPIO7 module (SWakeup signal) towards IPU2 + L3_MAIN1 + L4PER1 + L4PER2 + L4PER3 domains
    0=Dependency_is_disabled; 1=Dependency_is_enabled
  [0] WKUPDEP_GPIO7_IRQ1_MPU rw — Wakeup dependency from GPIO7 module (SWakeup signal) towards MPU + L3_MAIN1 + L4PER1 + L4PER2 + L4PER3 domains
    values as PM_L4PER_TIMER10_WKDEP.WKUPDEP_TIMER10_EVE4
0x114 RM_L4PER_GPIO7_CONTEXT reset 0x2 — This register contains dedicated GPIO7 context statuses. [warm reset insensitive]
  fields as RM_L4PER_GPIO2_CONTEXT
0x118 PM_L4PER_GPIO8_WKDEP — This register controls wakeup dependency based on GPIO8 service requests.
  [19] WKUPDEP_GPIO8_IRQ2_EVE4 rw — Wakeup dependency from GPIO8 module (SWakeup signal) towards EVE4 + L3_MAIN1 + L4PER1 + L4PER2 + L4PER3 domainsEVE4 is not supported in this family of devices.
    values as PM_L4PER_TIMER10_WKDEP.WKUPDEP_TIMER10_EVE4
  [18] WKUPDEP_GPIO8_IRQ2_EVE3 rw — Wakeup dependency from GPIO8 module (SWakeup signal) towards EVE3 + L3_MAIN1 + L4PER1 + L4PER2 + L4PER3 domainsEVE3 is not supported in this family of devices.
    values as PM_L4PER_TIMER10_WKDEP.WKUPDEP_TIMER10_EVE4
  [17] WKUPDEP_GPIO8_IRQ2_EVE2 rw — Wakeup dependency from GPIO8 module (SWakeup signal) towards EVE2 + L3_MAIN1 + L4PER1 + L4PER2 + L4PER3 domains
    values as PM_L4PER_TIMER10_WKDEP.WKUPDEP_TIMER10_EVE4
  [16] WKUPDEP_GPIO8_IRQ2_EVE1 rw — Wakeup dependency from GPIO8 module (SWakeup signal) towards EVE1 + L3_MAIN1 + L4PER1 + L4PER2 + L4PER3 domains
    values as PM_L4PER_TIMER10_WKDEP.WKUPDEP_TIMER10_EVE4
  [15] WKUPDEP_GPIO8_IRQ2_DSP2 rw — Wakeup dependency from GPIO8 module (SWakeup signal) towards DSP2 + L3_MAIN1 + L4PER1 + L4PER2 + L4PER3 domains
    values as PM_L4PER_TIMER10_WKDEP.WKUPDEP_TIMER10_EVE4
  [14] WKUPDEP_GPIO8_IRQ2_IPU1 rw — Wakeup dependency from GPIO8 module (SWakeup signal) towards IPU1 + L3_MAIN1 + L4PER1 + L4PER2 + L4PER3 domains
    values as PM_L4PER_TIMER10_WKDEP.WKUPDEP_TIMER10_EVE4
  [12] WKUPDEP_GPIO8_IRQ2_DSP1 rw — Wakeup dependency from GPIO8 module (SWakeup signal) towards DSP1 + L3_MAIN1 + L4PER1 + L4PER2 + L4PER3 domains
    values as PM_L4PER_TIMER10_WKDEP.WKUPDEP_TIMER10_EVE4
  [11] WKUPDEP_GPIO8_IRQ2_IPU2 rw — Wakeup dependency from GPIO8 module (SWakeup signal) towards IPU2 + L3_MAIN1 + L4PER1 + L4PER2 + L4PER3 domains
    0=Dependency_is_disabled; 1=Dependency_is_enabled
  [10] WKUPDEP_GPIO8_IRQ2_MPU rw — Wakeup dependency from GPIO8 module (SWakeup signal) towards MPU + L3_MAIN1 + L4PER1 + L4PER2 + L4PER3 domains
    values as PM_L4PER_TIMER10_WKDEP.WKUPDEP_TIMER10_EVE4
  [9] WKUPDEP_GPIO8_IRQ1_EVE4 rw — Wakeup dependency from GPIO8 module (SWakeup signal) towards EVE4 + L3_MAIN1 + L4PER1 + L4PER2 + L4PER3 domainsEVE4 is not supported in this family of devices.
    values as PM_L4PER_TIMER10_WKDEP.WKUPDEP_TIMER10_EVE4
  [8] WKUPDEP_GPIO8_IRQ1_EVE3 rw — Wakeup dependency from GPIO8 (SWakeup signal) towards EVE3 + L3_MAIN1 + L4PER1 + L4PER2 + L4PER3 domainsEVE3 is not supported in this family of devices.
    values as PM_L4PER_TIMER10_WKDEP.WKUPDEP_TIMER10_EVE4
  [7] WKUPDEP_GPIO8_IRQ1_EVE2 rw — Wakeup dependency from GPIO8 module (SWakeup signal) towards EVE2 + L3_MAIN1 + L4PER1 + L4PER2 + L4PER3 domains
    values as PM_L4PER_TIMER10_WKDEP.WKUPDEP_TIMER10_EVE4
  [6] WKUPDEP_GPIO8_IRQ1_EVE1 rw — Wakeup dependency from GPIO8 module (SWakeup signal) towards EVE1 + L3_MAIN1 + L4PER1 + L4PER2 + L4PER3 domains
    values as PM_L4PER_TIMER10_WKDEP.WKUPDEP_TIMER10_EVE4
  [5] WKUPDEP_GPIO8_IRQ1_DSP2 rw — Wakeup dependency from GPIO8 module (SWakeup signal) towards DSP2 + L3_MAIN1 + L4PER1 + L4PER2 + L4PER3 domains
    values as PM_L4PER_TIMER10_WKDEP.WKUPDEP_TIMER10_EVE4
  [4] WKUPDEP_GPIO8_IRQ1_IPU1 rw — Wakeup dependency from GPIO8 module (SWakeup signal) towards IPU1 + L3_MAIN1 + L4PER1 + L4PER2 + L4PER3 domains
    values as PM_L4PER_TIMER10_WKDEP.WKUPDEP_TIMER10_EVE4
  [2] WKUPDEP_GPIO8_IRQ1_DSP1 rw — Wakeup dependency from GPIO8 module (SWakeup signal) towards DSP1 + L3_MAIN1 + L4PER1 + L4PER2 + L4PER3 domains
    values as PM_L4PER_TIMER10_WKDEP.WKUPDEP_TIMER10_EVE4
  [1] WKUPDEP_GPIO8_IRQ1_IPU2 rw — Wakeup dependency from GPIO8 module (SWakeup signal) towards IPU2 + L3_MAIN1 + L4PER1 + L4PER2 + L4PER3 domains
    0=Dependency_is_disabled; 1=Dependency_is_enabled
  [0] WKUPDEP_GPIO8_IRQ1_MPU rw — Wakeup dependency from GPIO8 module (SWakeup signal) towards MPU + L3_MAIN1 + L4PER1 + L4PER2 + L4PER3 domains
    values as PM_L4PER_TIMER10_WKDEP.WKUPDEP_TIMER10_EVE4
